# PIC32CX0525SG12144 register map
Vendor: Microchip Technology; Series: 0525SG12; File version: 0
CPU: CM4 r1p0, little endian, no MPU, no FPU, 3 interrupt priority bits, 172 interrupts
Registers are 32-bit, read-write, reset 0x0 unless marked. A register's access mark holds for its fields unless they carry their own. Offsets are from the block's base; [hi:lo] are bit positions; lines under a group give offsets from that group; {n}, {i} and the like mark numbered series.

## MBX — The Mailbox provides a standard run-time mechanism for the host to communicate with the Embedded Controller (EC).
Base 0x400F0000
0x00 RT_IDX 8-bit — MBX_Index Register
0x01 RT_DATA 8-bit — MBX_Data_Register
0x100 H2EC — If enabled, an interrupt to the EC marked by the MBX_DATA bit in the Interrupt Aggregator will be generated whenever the Host writes this register. This register is cleared when written with FFh.
0x104 EC2H 8-bit — An EC write to this register will set bit EC_WR in the SMI Interrupt Source Register to '1b'. If enabled, this will generate a Host SMI. This register is cleared when written with FFh.
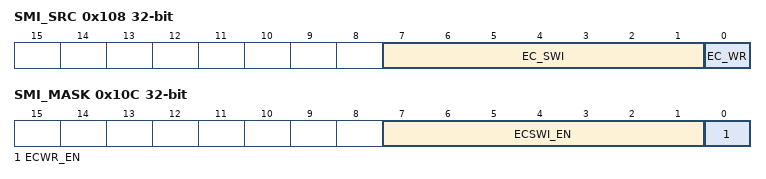
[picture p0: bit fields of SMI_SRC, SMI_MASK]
0x108 SMI_SRC — SMI Interrupt Source Register
  [7:1] EC_SWI — EC Software Interrupt. An SIRQ to the Host is generated when any bit in this register when this bit is set to '1b' and the corresponding bit in the SMI Interrupt Mask Register register is '1b'.
  [0] EC_WR — EC Mailbox Write. This bit is set automatically when the EC-to-Host Mailbox Register has been written. An SMI or SIRQ to the Host is generated when n this bit is '1b' and the corresponding bit in the SMI Interrupt Mask Register register is '1b'. This bit is automatically cleared by a read of the EC-to-Host Mailbox Register through the Host Access Port.
0x10C SMI_MASK — SMI Interrupt Mask Register
  [7:1] ECSWI_EN — EC Software Interrupt Enable. If this bit is '1b', the bit EC_WR in the SMI Interrupt Source Register is enabled for the generation of SIRQ or nSMI events.
  [0] ECWR_EN — EC Mailbox Write.Interrupt Enable. Each bit in this field that is '1b' enables the generation of SIRQ interrupts when the corresponding bit in the EC_SWI field in the SMI Interrupt Source Register is '1b'.
{0x110+4i} MBX_REG[{i}] (i=0..7) group
  0x00 u32 — SOURCE
  {0x0+2j} u16[{j}] (j=0..1) 16-bit — ENABLE SET
  {0x0+j} u08[{j}] (j=0..3) 8-bit — RESULT

## WDT — The function of the Watchdog Timer is to provide a mechanism to detect if the internal embedded controller has failed.
Base 0x40000400
0x00 LOAD 16-bit reset 0xFFFF — Writing this field reloads the Watch Dog Timer counter.
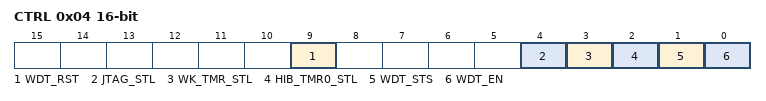
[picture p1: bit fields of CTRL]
0x04 CTRL 16-bit — WDT Control Register
  [9] WDT_RST — If the WDT_RESET bit is set and the watch dog timer expires, the Watch dog module will generate interrupt and clear the WDT_RESET to 0b.
  [4] JTAG_STL — This bit enables the WDT Stall function if JTAG or SWD debug functions are active. 1=The WDT is stalled while either JTAG or SWD is active. 0=The WDT is not affected by the JTAG debug interface.
  [3] WK_TMR_STL — This bit enables the WDT Stall function if the Week Timer is active. 1=The WDT is stalled while the Week Timer is active. 0=The WDT is not affected by the Week Timer.
  [2] HIB_TMR0_STL — This bit enables the WDT Stall function if the Hibernation Timer 0 is active. 1=The WDT is stalled while the Hibernation Timer 0 is active. 0=The WDT is not affected by Hibernation Timer 0.
  [1] WDT_STS — WDT_STATUS is set by hardware if the last reset of the device was caused by an underflow of the WDT. This bit must be cleared by the EC firmware writing a '1' to this bit. Writing a '0' to this bit has no effect.
  [0] WDT_EN — WDT Block enabled
0x08 KICK 8-bit wo — The WDT Kick Register is a strobe. Reads of this register return 0. Writes to this register cause the WDT to reload the WDT Load Register value and start decrementing when the WDT_ENABLE bit in the WDT Control Register is set to '1'. When the WDT_ENABLE bit in the WDT Control Register is cleared to '0', writes to the WDT Kick Register have no effect.
0x0C CNT 16-bit ro reset 0xFFFF — This read-only register provides the current WDT count.
0x10 STS 8-bit — This register provides the current WDT count.
  [0] WDT_EV_IRQ — WDT_EVENT_IRQ : This bit indicates the status of interrupt from Watch dog module.
0x14 IEN 8-bit — Watch Dog Interrupt Enable Register.
  [0] WDT_INTEN — WDT_Int_Enable: This is the interrupt enables bit for WDT_INT interrupt. 1= WDT_INT Interrupt Enable 0= WDT_INT Interrupt Disabled
